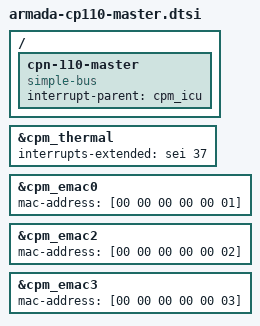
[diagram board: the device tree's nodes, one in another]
/****************************************************************************
* This program is free software: you can redistribute it and/or modify it
* under the terms of the GNU General Public License as published by the Free
* Software Foundation, either version 2 of the License, or any later version.
*
* This program is distributed in the hope that it will be useful,
* but WITHOUT ANY WARRANTY; without even the implied warranty of
* MERCHANTABILITY or FITNESS FOR A PARTICULAR PURPOSE.  See the
* GNU General Public License for more details.
*
* You should have received a copy of the GNU General Public License
* along with this program.  If not, see <http://www.gnu.org/licenses/>.
* ***************************************************************************
*/

/*
 * Device Tree file for Marvell Armada CPN-110 Master.
 */

#include "armada-common.dtsi"

#include <dt-bindings/phy/phy-comphy-mvebu.h>

#define CP110_NAME		cpm
#define CP110_BASE		0xf2000000
#define CP110_PCIE_IO_BASE	0xf9000000
#define CP110_PCIE_MEM_BASE	0xf6000000
#define CP110_SPI_BUS_ID(n)	(0 + (n))
#define CP110_EIP197_INDEX	0

/ {
	cpn-110-master {
		#address-cells = <2>;
		#size-cells = <2>;
		compatible = "simple-bus";
		interrupt-parent = <&cpm_icu>;
		ranges;

		#include "armada-cp110.dtsi"
	};
};
#undef CP110_NAME
#undef CP110_BASE
#undef CP110_PCIE_IO_BASE
#undef CP110_PCIE_MEM_BASE
#undef CP110_SPI_BUS_ID
#undef CP110_EIP197_INDEX

&cpm_thermal {
	/* interrupt assignment by ICU supports single thermal sensor unit,
	* currently cp0 thermal sensor irq only is enabled.
	* To enable cp1 thermal sensor interrupt,
	* first disable cp0 thermal sensor interrupt.
	*/
	interrupts-extended = <&sei 37>;
};

&cpm_emac0 {
	mac-address = [00 00 00 00 00 01];
};

&cpm_emac2 {
	mac-address = [00 00 00 00 00 02];
};

&cpm_emac3 {
	mac-address = [00 00 00 00 00 03];
};
